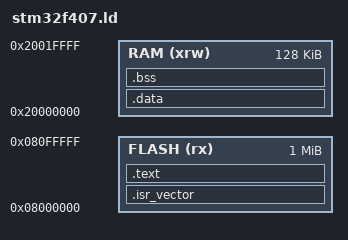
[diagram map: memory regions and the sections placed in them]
ENTRY(Reset_Handler)

_estack = ORIGIN(RAM) + LENGTH(RAM);

MEMORY
{
    FLASH (rx)  : ORIGIN = 0x08000000, LENGTH = 1024K
    RAM (xrw)   : ORIGIN = 0x20000000, LENGTH = 128K
}

SECTIONS
{
    .isr_vector :
    {
        . = ALIGN(4);
        KEEP(*(.isr_vector))
        . = ALIGN(4);
    } > FLASH

    .text :
    {
        . = ALIGN(4);
        KEEP(*(.init))
        *(.text*)
        *(.rodata*)
        KEEP(*(.fini))
        . = ALIGN(4);
        _etext = .;
    } > FLASH

    .data : AT(_etext)
    {
        . = ALIGN(4);
        _sdata = .;
        *(.data*)
        . = ALIGN(4);
        _edata = .;
    } > RAM

    _sidata = LOADADDR(.data);

    .bss :
    {
        . = ALIGN(4);
        _sbss = .;
        *(.bss*)
        *(COMMON)
        . = ALIGN(4);
        _ebss = .;
    } > RAM

    end = .;

    /DISCARD/ :
    {
        *(.ARM.exidx*)
        *(.ARM.extab*)
        *(.note.GNU-stack)
        *(.comment)
    }
}
